# STM32F410Cx register map
File version: 1.0
Registers are 32-bit, read-write, reset 0x0 unless marked. A register's access mark holds for its fields unless they carry their own. Offsets are from the block's base; [hi:lo] are bit positions; {n}, {i} and the like mark numbered series.

## DAC — Digital to Analog Converter
Base 0x40007400
Same registers: DAC1 0x40007400 (alternate view of DAC)
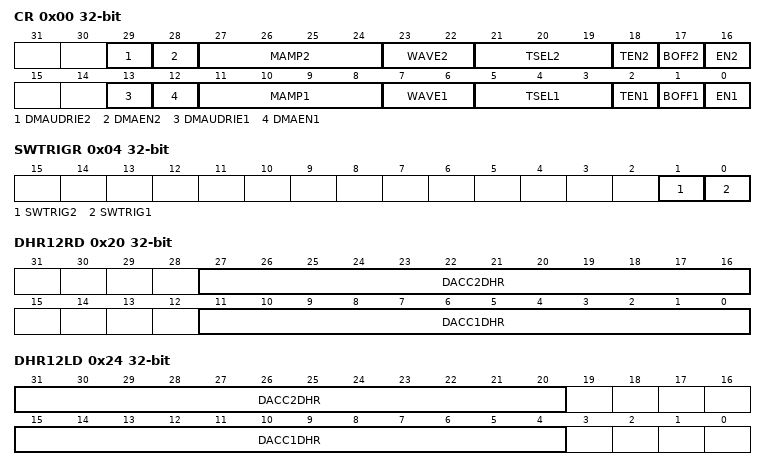
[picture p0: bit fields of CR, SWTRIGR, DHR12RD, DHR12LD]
0x00 CR — DAC control register
  [29] DMAUDRIE2 — DAC channel2 DMA underrun interrupt enable
  [28] DMAEN2 — DAC channel2 DMA enabled
  [27:24] MAMP2 — MAMP2[3:0] (DAC channel2 Mask/Amplitude selector)
  [23:22] WAVE2 — WAVE2[1:0] (DAC channel2 noise/triangle wave generation enable)
  [21:19] TSEL2 — TSEL2[2:0] (DAC channel2 Trigger selection)
  [18] TEN2 — DAC channel2 Trigger enable
  [17] BOFF2 — DAC channel2 output buffer disable
  [16] EN2 — DAC channel2 enable
  [13] DMAUDRIE1 — DAC channel1 DMA underrun interrupt enable
  [12] DMAEN1 — DAC channel1 DMA enable
  [11:8] MAMP1 — MAMP1[3:0] (DAC channel1 Mask/Amplitude selector)
  [7:6] WAVE1 — WAVE1[1:0] (DAC channel1 noise/triangle wave generation enable)
  [5:3] TSEL1 — TSEL1[2:0] (DAC channel1 Trigger selection)
  [2] TEN1 — DAC channel1 Trigger enable
  [1] BOFF1 — DAC channel1 output buffer disable
  [0] EN1 — DAC channel1 enable
0x04 SWTRIGR — DAC software trigger register
  [1] SWTRIG2 — DAC channel2 software trigger
  [0] SWTRIG1 — DAC channel1 software trigger
0x08 DHR12R1 — DAC channel1 12-bit right-aligned data holding register
  [11:0] DACC1DHR — DAC channel1 12-bit Right aligned data
0x0C DHR12L1 — DAC channel1 12-bit left aligned data holding register
  [15:4] DACC1DHR — DAC channel1 12-bit Left aligned data
0x10 DHR8R1 — DAC channel1 8-bit right aligned data holding register
  [7:0] DACC1DHR — DAC channel1 8-bit Right aligned data
0x14 DHR12R2 — DAC channel2 12-bit right aligned data holding register
  [11:0] DACC2DHR — DAC channel2 12-bit Right aligned data
0x18 DHR12L2 — DAC channel2 12-bit left aligned data holding register
  [15:4] DACC2DHR — DAC channel2 12-bit Left aligned data
0x1C DHR8R2 — DAC channel2 8-bit right-aligned data holding register
  [7:0] DACC2DHR — DAC channel2 8-bit Right aligned data
0x20 DHR12RD — Dual DAC 12-bit right-aligned data holding register
  [27:16] DACC2DHR — DAC channel2 12-bit Right aligned data
  [11:0] DACC1DHR — DAC channel1 12-bit Right aligned data
0x24 DHR12LD — DUAL DAC 12-bit left aligned data holding register
  [31:20] DACC2DHR — DAC channel2 12-bit Left aligned data
  [15:4] DACC1DHR — DAC channel1 12-bit Left aligned data
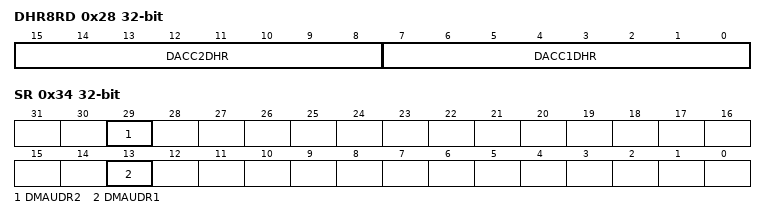
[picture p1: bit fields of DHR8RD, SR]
0x28 DHR8RD — DUAL DAC 8-bit right aligned data holding register
  [15:8] DACC2DHR — DAC channel2 8-bit Right aligned data
  [7:0] DACC1DHR — DAC channel1 8-bit Right aligned data
0x2C DOR1 — DAC channel1 data output register
  [11:0] DACC1DOR — DAC channel1 data output
0x30 DOR2 — DAC channel2 data output register
  [11:0] DACC2DOR — DAC channel2 data output
0x34 SR — DAC status register
  [29] DMAUDR2 — DAC channel2 DMA underrun flag
  [13] DMAUDR1 — DAC channel1 DMA underrun flag

## SYSCFG — System configuration controller
Base 0x40013800
0x00 MEMRMP — SYSCFG memory remap register
  [1:0] MEM_MODE — SYSCFG_Memory Remap Config
    0=FLASH (Main Flash memory mapped at 0x00000000); 1=SYSTEMFLASH (System Flash memory mapped at 0x00000000); 3=SRAM (SRAM1 mapped at 0x00000000)
0x04 PMC — SYSCFG peripheral mode configuration register
  [16] ADC1DC2 — Refer to AN4073 on how to use this bit
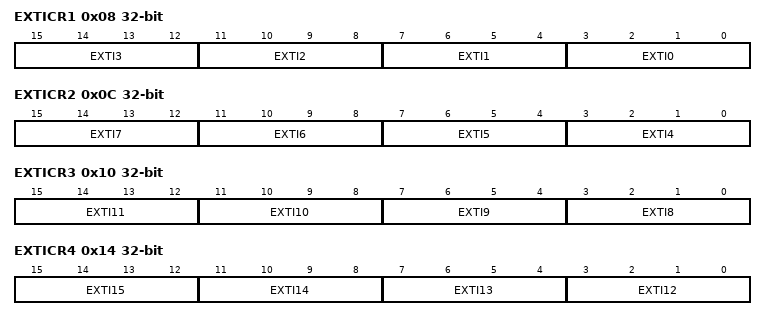
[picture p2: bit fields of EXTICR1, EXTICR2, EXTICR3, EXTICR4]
0x08 EXTICR1 — SYSCFG external interrupt configuration registers
  [4n+3:4n] EXTI{n} (n=0..3) — EXTI {n} configuration
0x0C EXTICR2 — SYSCFG external interrupt configuration registers
  [4n-13:4n-16] EXTI{n} (n=4..7) — EXTI {n} configuration
0x10 EXTICR3 — SYSCFG external interrupt configuration registers
  [4n-29:4n-32] EXTI{n} (n=8..11) — EXTI {n} configuration
0x14 EXTICR4 — SYSCFG external interrupt configuration registers
  [4n-45:4n-48] EXTI{n} (n=12..15) — EXTI {n} configuration
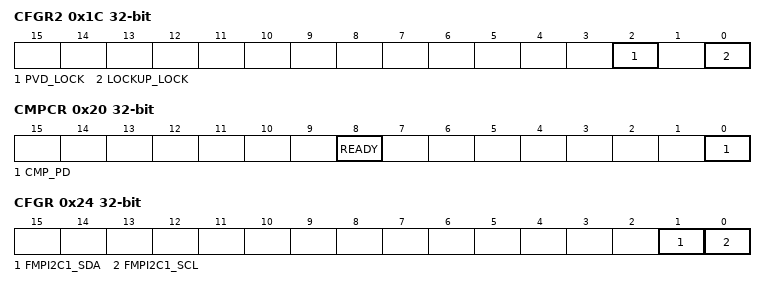
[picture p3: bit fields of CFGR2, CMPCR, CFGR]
0x1C CFGR2 — SYSCFG Configuration register2
  [2] PVD_LOCK
  [0] LOCKUP_LOCK — Core Lockup lock
0x20 CMPCR — SYSCFG Compensation cell control register
  [8] READY — Compensation cell power-down
  [0] CMP_PD — Compensation cell ready flag
0x24 CFGR — SYSCFG Configuration register
  [1] FMPI2C1_SDA — FM+ drive capability for FMPI2C1_SDA pin
  [0] FMPI2C1_SCL — FM+ drive capability for FMPI2C1_SCL pin
